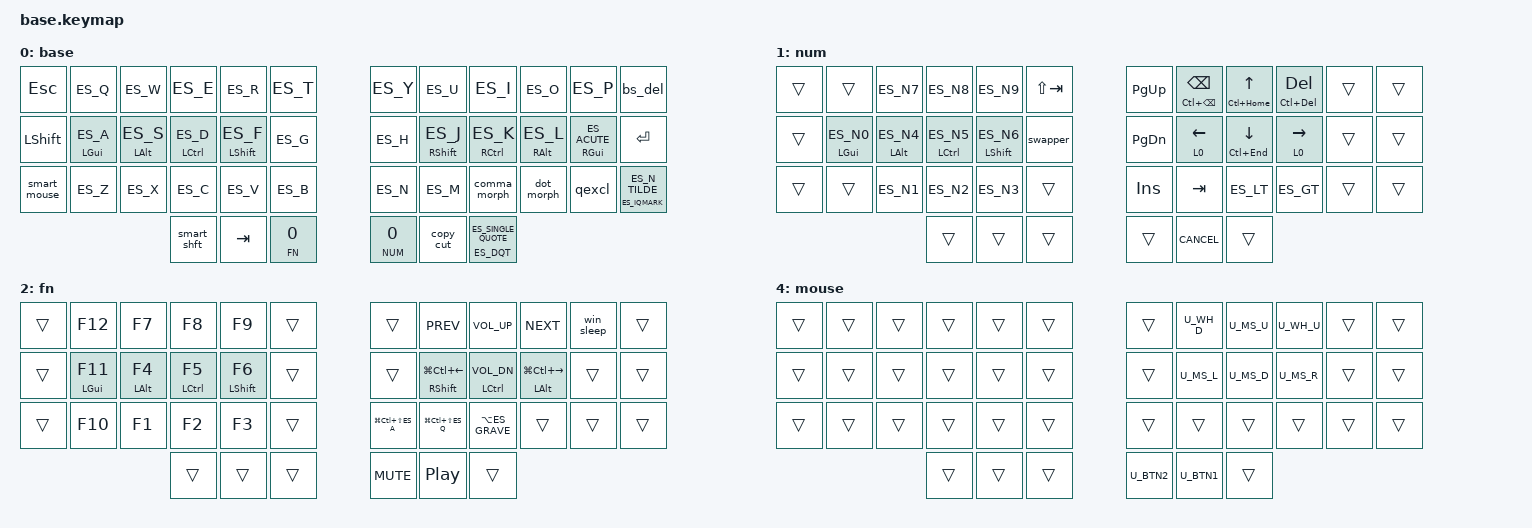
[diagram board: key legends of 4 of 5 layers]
#include "keys_es.h"
#include <behaviors.dtsi>
#include <dt-bindings/zmk/keys.h>
#if CONFIG_WIRELESS
    #include <dt-bindings/zmk/bt.h>
    #define _BT_SEL_KEYS_ &bt BT_SEL 0 &bt BT_SEL 1 &bt BT_SEL 2 &bt BT_SEL 3 &bt BT_CLR
#else
    #define _BT_SEL_KEYS_ &trans &trans &trans &trans &trans
#endif

#include "../zmk-nodefree-config/helper.h"

#define DEF 0
#define NUM 1
#define FN 2
#define SYS 3
#define MOUSE 4

#include "combos.dtsi"  // requires layer aliases
#include "mouse.dtsi"

#define XXX &none
#define ___ &trans

/* Global settings */

#define QUICK_TAP_MS 175

&sk {  // sticky-key config
    release-after-ms = <900>;  // release after 0.6s
    quick-release;             // no double capitalization when rolling keys
};

&sl {  // sticky-layer config
    ignore-modifiers;          // allow chording sticky mods & layers
};

&lt {  // layer-tap config
    flavor = "balanced";
    tapping-term-ms = <200>;
    quick-tap-ms = <QUICK_TAP_MS>;
};

/* Homerow mods */

#define KEYS_L LT0 LT1 LT2 LT3 LT4 LT5 LM0 LM1 LM2 LM3 LM4 LM5 LB0 LB1 LB2 LB3 LB4 LB5  // left hand
#define KEYS_R RT0 RT1 RT2 RT3 RT4 RT5 RM0 RM1 RM2 RM3 RM4 RM5 RB0 RB1 RB2 RB3 RB4 RB5 // right hand
#define THUMBS LH2 LH1 LH0 RH0 RH1 RH2                                      // thumbs

#define MAKE_HRM(NAME, HOLD, TAP, TRIGGER_POS) \
    ZMK_BEHAVIOR(NAME, hold_tap, \
        flavor = "balanced"; \
        tapping-term-ms = <280>; \
        quick-tap-ms = <QUICK_TAP_MS>; \
        require-prior-idle-ms = <150>; \
        bindings = <HOLD>, <TAP>; \
        hold-trigger-key-positions = <TRIGGER_POS>; \
        hold-trigger-on-release; \
    )
MAKE_HRM(hml, &kp, &kp, KEYS_R THUMBS)  // left-hand HRMs
MAKE_HRM(hmr, &kp, &kp, KEYS_L THUMBS)  // right-hand HRMs

MAKE_HRM(hml_repeat, &kp, &key_repeat, KEYS_R THUMBS)  // used for HRM-combo
MAKE_HRM(hmr_lpar_lt, &kp, &lpar_lt, KEYS_L THUMBS)    // "    "   "   "
MAKE_HRM(hmr_rpar_gt, &kp, &rpar_gt, KEYS_L THUMBS)    // "    "   "   "

/* Nav cluster */

// long-tap action on hold, short-tap action on all interrupts
#define MT_CORE \
    flavor = "tap-preferred"; \
    tapping-term-ms = <220>; \
    quick-tap-ms = <220>; \
    hold-trigger-key-positions = <0>;

&mt { MT_CORE };
ZMK_BEHAVIOR(mt_home, hold_tap, bindings = <&masked_home>, <&kp>; MT_CORE)
ZMK_BEHAVIOR(mt_end,  hold_tap,  bindings = <&masked_end>, <&kp>; MT_CORE)

#define NAV_LEFT  &mt_home 0   LEFT    // tap: left  | long-tap: beginning of line
#define NAV_RIGHT &mt_end 0    RIGHT   // tap: right | long-tap: end       of line
#define NAV_UP    &mt LC(HOME) UP      // tap: up    | long-tap: beginning of document
#define NAV_DOWN  &mt LC(END)  DOWN    // tap: down  | long-tap: end       of document
#define NAV_BSPC  &mt LC(BSPC) BSPC    // tap: bspc  | long-tap: delete word backward
#define NAV_DEL   &mt LC(DEL)  DEL     // tap: del   | long-tap: delete word forward

// mask CTRL when holding left/right to avoid accidental jumps to beginning/end of document
#define MASK_MODS(NAME, MODS, BINDING) \
    ZMK_BEHAVIOR(NAME, mod_morph, \
        bindings = <BINDING>, <BINDING>; \
        mods = <MODS>; \
    )
MASK_MODS(masked_home, (MOD_LCTL), &kp HOME)
MASK_MODS(masked_end,  (MOD_LCTL), &kp END)

/* Caps-word, num-word and smart-mouse */

// tap: sticky-shift | shift + tap/ double-tap: caps-word | hold: shift
ZMK_BEHAVIOR(smart_shft, mod_morph,
    bindings = <&sk LSHFT>, <&caps_word>;
    mods = <(MOD_LSFT)>;
)
&caps_word {  // mods deactivate caps-word, requires PR #1451
    /delete-property/ ignore-modifiers;
};

// tap: num-word | double-tap: sticky num-layer | hold: num-layer
#define SMART_NUM &smart_num NUM 0
ZMK_BEHAVIOR(smart_num, hold_tap,
    flavor = "balanced";
    tapping-term-ms = <200>;
    quick-tap-ms = <QUICK_TAP_MS>;
    bindings = <&mo>, <&num_dance>;
)
ZMK_BEHAVIOR(num_dance, tap_dance,
    tapping-term-ms = <200>;
    bindings = <&num_word>, <&sl NUM>;  // reverse this for sticky-num on single tap
)
&num_word {  // num-word, requires PR #1451
    layers = <NUM>;
    continue-list = <BSPC DEL ES_DOT ES_COMMA ES_PLUS MINUS ES_STAR ES_FSLH ES_EQUAL>;
};

// smart-mouse, requires PR #1366
ZMK_BEHAVIOR(smart_mouse, tri_state,
    bindings = <&tog MOUSE>, <&none>, <&tog MOUSE>;
    ignored-key-positions = <LT1 LT3 RT1 RT2 RT3 RM1 RM2 RM3 RH0 RH1>;
    ignored-layers = <MOUSE>;
)

/* Custom behaviors */

// Alt+Tab swapper, requires PR #1366
ZMK_BEHAVIOR(swapper, tri_state,
    bindings = <&kt LALT>, <&kp TAB>, <&kt LALT>;
    ignored-key-positions = <LT2>;
)

// tap: comma | shift + tap: semicolon | ctrl + shift + tap: <
ZMK_BEHAVIOR(comma_morph, mod_morph,
    mods = <(MOD_LSFT|MOD_RSFT)>;
    bindings = <&kp ES_COMMA>, <&comma_inner_morph>;
)
ZMK_BEHAVIOR(comma_inner_morph, mod_morph,
    bindings = <&kp ES_SEMICOLON>, <&kp ES_LESS_THAN>;
    mods = <(MOD_LCTL|MOD_RCTL)>;
)

// tap: dot | shift + tap: colon | ctrl + shift + tap: >
ZMK_BEHAVIOR(dot_morph, mod_morph,
    bindings = <&kp ES_DOT>, <&dot_inner_morph>;
    mods = <(MOD_LSFT|MOD_RSFT)>;
)
ZMK_BEHAVIOR(dot_inner_morph, mod_morph,
    bindings = <&kp ES_COLON>, <&kp ES_GREATER_THAN>;
    mods = <(MOD_LCTL|MOD_RCTL)>;
)

// tap: qmark | shift + tap: excl
ZMK_BEHAVIOR(qexcl, mod_morph,
    bindings = <&kp ES_QMARK>, <&kp ES_EXCL>;
    mods = <(MOD_LSFT|MOD_RSFT)>;
)

// tap: space | shift + tap: dot -> space -> sticky shift | hold: activate layer
ZMK_BEHAVIOR(lt_spc, hold_tap,
    flavor = "balanced";
    tapping-term-ms = <200>;
    quick-tap-ms = <QUICK_TAP_MS>;
    bindings = <&mo>, <&spc_morph>;
)
ZMK_BEHAVIOR(spc_morph, mod_morph,
    bindings = <&kp ES_SPACE>, <&dot_spc>;
    mods = <(MOD_LSFT|MOD_RSFT)>;
)
ZMK_BEHAVIOR(dot_spc, macro,
    wait-ms = <0>;
    tap-ms = <5>;
    bindings = <&kp ES_DOT &kp ES_SPACE &sk LSHFT>;
)

// tap: backspace | lshft + tap: delete | rshft + tap: shift-delete
ZMK_BEHAVIOR(bs_del, mod_morph,
    bindings = <&kp BSPC>, <&kp DEL>;
    mods = <(MOD_LSFT|MOD_RSFT)>;
    keep-mods = <MOD_RSFT>;
)

// tap: left-parenthesis | shft + tap: less-than
ZMK_BEHAVIOR(lpar_lt, mod_morph,
    bindings = <&kp ES_LPAR>, <&kp ES_LT>;
    mods = <(MOD_LSFT|MOD_RSFT)>;
)

// tap: right-parenthesis | shft + tap: greater-than
ZMK_BEHAVIOR(rpar_gt, mod_morph,
    bindings = <&kp ES_RPAR>, <&kp ES_GT>;
    mods = <(MOD_LSFT|MOD_RSFT)>;
)

// tap: copy | double-tap: cut
ZMK_BEHAVIOR(copy_cut, tap_dance,
    tapping-term-ms = <200>;
    bindings = <&kp LC(INS)>, <&kp LC(ES_X)>;
)

// Windows sleep key
ZMK_BEHAVIOR(win_sleep, macro,
    wait-ms = <500>;
    tap-ms = <50>;
    bindings = <&kp LG(ES_X) &kp ES_U &kp ES_S>;
)

// misc aliases
#define CANCEL      &kp K_CANCEL             // cancel caps-word, num-word and smart-mouse
#define DSK_PREV    &hmr RSHFT LG(LC(LEFT))  // previous desktop
#define DSK_NEXT    &hmr LALT LG(LC(RIGHT))  // next     desktop
#define PIN_WIN     &kp LG(LC(LS(ES_Q)))        // pin window across desktops
#define PIN_APP     &kp LG(LC(LS(ES_A)))        // pin application across desktops
#define DSK_MGR     &kp LA(ES_GRAVE)            // desktop manager
#define VOL_DOWN    &hmr LCTRL C_VOL_DN

/* Keymap */

ZMK_CONDITIONAL_LAYER(FN NUM, SYS)  // FN + NUM --> SYS


ZMK_LAYER(base,
//╭────────────┼──────────────┬──────────────┬───────────────┬────────────────┬──────────────╮  ╭─────────────┬────────────────┬──────────────┬─────────────┬───────────────┬──────────╮
    &kp ESC      &kp ES_Q       &kp ES_W       &kp ES_E        &kp ES_R         &kp ES_T          &kp ES_Y      &kp ES_U         &kp ES_I       &kp ES_O      &kp ES_P        &bs_del 
//├────────────┼──────────────┼──────────────┼───────────────┼────────────────┼──────────────┤  ├─────────────┼────────────────┼──────────────┼─────────────┼───────────────┼──────────┤
    &kp LSHIFT   &hml LGUI ES_A &hml LALT ES_S &hml LCTRL ES_D &hml LSHIFT ES_F &kp ES_G          &kp ES_H      &hml RSHFT ES_J  &hml RCTRL ES_K &hml RALT ES_L &hml RGUI ES_ACUTE &kp RET 
//├────────────┼──────────────┼──────────────┼───────────────┼────────────────┼──────────────┤  ├─────────────┼────────────────┼──────────────┼─────────────┼───────────────┼──────────┤
    &smart_mouse &kp ES_Z       &kp ES_X       &kp ES_C        &kp ES_V         &kp ES_B          &kp ES_N      &kp ES_M         &comma_morph   &dot_morph    &qexcl          &mt ES_IQMARK ES_N_TILDE
//╰────────────┤──────────────┼──────────────┴───────────────┼────────────────┼──────────────┤  ├─────────────┼────────────────┼──────────────┴─────────────┴───────────────┴──────────╯
                                               &smart_shft     &kp TAB          &lt_spc FN 0      &lt_spc NUM 0 &copy_cut        &mt ES_DQT ES_SINGLE_QUOTE                                   
//                                           ╰───────────────┴────────────────┴──────────────╯  ╰─────────────┴────────────────┴──────────────╯  
)

ZMK_LAYER(num,
//╭──────┬────────────────┬────────────────┬─────────────────┬─────────────────┬─────────────╮  ╭─────────────┬─────────────┬─────────────┬─────────────┬─────────────┬────────╮
    ___     ___             &kp ES_N7        &kp ES_N8         &kp ES_N9         &kp LS(TAB)      &kp PG_UP     NAV_BSPC      NAV_UP        NAV_DEL       ___             ___
//├──────┼────────────────┼────────────────┼─────────────────┼─────────────────┼─────────────┤  ├─────────────┼─────────────┼─────────────┼─────────────┼─────────────┼────────┤
    ___    &hml LGUI ES_N0  &hml LALT ES_N4  &hml LCTRL ES_N5  &hml LSHFT ES_N6  &swapper         &kp PG_DN     NAV_LEFT      NAV_DOWN      NAV_RIGHT     ___             ___
//├──────┼────────────────┼────────────────┼─────────────────┼─────────────────┼─────────────┤  ├─────────────┼─────────────┼─────────────┼─────────────┼─────────────┼────────┤
    ___     ___             &kp ES_N1        &kp ES_N2         &kp ES_N3         ___              &kp INS       &kp TAB       &kp ES_LT     &kp ES_GT        ___             ___
//╰──────┴────────────────┴────────────────┴─────────────────┼─────────────────┼─────────────┤  ├─────────────┼─────────────┼─────────────┴─────────────┴─────────────┴────────╯
                                             ___              ___               ___               ___           CANCEL       ___                                             
//                                         ╰─────────────────┴─────────────────┴─────────────╯  ╰─────────────┴─────────────┴─────────────╯                                    
)

ZMK_LAYER(fn,
//╭──────┬─────────────┬─────────────┬─────────────┬─────────────┬─────────────╮  ╭─────────────┬─────────────┬─────────────┬─────────────┬─────────────┬────────╮
    ___    &kp F12       &kp F7        &kp F8        &kp F9        ___              ___           &kp C_PREV    &kp C_VOL_UP  &kp C_NEXT    &win_sleep      ___
//├──────┼─────────────┼─────────────┼─────────────┼─────────────┼─────────────┤  ├─────────────┼─────────────┼─────────────┼─────────────┼─────────────┼────────┤
    ___    &hml LGUI F11 &hml LALT F4  &hml LCTRL F5 &hml LSHFT F6 ___              ___           DSK_PREV      VOL_DOWN      DSK_NEXT      ___             ___
//├──────┼─────────────┼─────────────┼─────────────┼─────────────┼─────────────┤  ├─────────────┼─────────────┼─────────────┼─────────────┼─────────────┼────────┤
    ___    &kp F10       &kp F1        &kp F2        &kp F3        ___              PIN_APP       PIN_WIN       DSK_MGR       ___           ___             ___
//╰──────┴─────────────┴─────────────┴─────────────┼─────────────┼─────────────┤  ├─────────────┼─────────────┼─────────────┴───────────────────────────┴────────╯
                                        ___           ___           ___              &kp C_MUTE    &kp C_PP         ___
//                                   ╰─────────────┴─────────────┴─────────────╯  ╰─────────────┴─────────────┴─────────────╯
)

ZMK_LAYER(sys,
//╭──────┬─────────────┬─────────────┬──────────────┬─────────────┬─────────────╮  ╭─────────────┬─────────────┬─────────────┬─────────────┬─────────────┬────────╮
    ___                                _BT_SEL_KEYS_                                 ___           ___           ___           ___           ___             ___
//├──────┼─────────────┼─────────────┼──────────────┼─────────────┼─────────────┤  ├─────────────┼─────────────┼─────────────┼─────────────┼─────────────┼────────┤
    ___     ___           ___           ___           ___           &kp C_POWER      &kp C_POWER   ___           ___           ___             ___
//├──────┼─────────────┼─────────────┼──────────────┼─────────────┼─────────────┤  ├─────────────┼─────────────┼─────────────┼─────────────┼─────────────┼────────┤
    ___     ___           ___           ___           &bootloader   &sys_reset       &sys_reset    &bootloader   ___           ___           ___           ___    
//╰──────┴─────────────┴─────────────┴──────────────┼─────────────┼─────────────┤  ├─────────────┼─────────────┼─────────────┴───────────────────────────┴────────╯
                                        ___           ___          ___               ___           ___            ___
//                                   ╰──────────────┴─────────────┴─────────────╯  ╰─────────────┴─────────────┴─────────────╯
)

ZMK_LAYER(mouse,
//╭──────┬─────────────┬─────────────┬─────────────┬─────────────┬─────────────╮  ╭─────────────┬─────────────┬─────────────┬─────────────┬─────────────┬────────╮
    ___     ___           ___           ___           ___           ___              ___           U_WH_D        U_MS_U         U_WH_U       ___             ___
//├──────┼─────────────┼─────────────┼─────────────┼─────────────┼─────────────┤  ├─────────────┼─────────────┼─────────────┼─────────────┼─────────────┼────────┤
    ___     ___           ___           ___           ___           ___              ___           U_MS_L        U_MS_D         U_MS_R       ___             ___
//├──────┼─────────────┼─────────────┼─────────────┼─────────────┼─────────────┤  ├─────────────┼─────────────┼─────────────┼─────────────┼─────────────┼────────┤
    ___     ___           ___           ___           ___           ___              ___           ___           ___            ___          ___             ___
//╰──────┴─────────────┼─────────────┴─────────────┼─────────────┼─────────────┤  ├─────────────┼─────────────┼─────────────┴───────────────────────────┴────────╯
                                        ___           ___           ___              U_BTN2        U_BTN1          ___
//                                   ╰─────────────┴─────────────┴─────────────╯  ╰─────────────┴─────────────┴─────────────╯
)

/* vim: set ft=c tw=174: */
